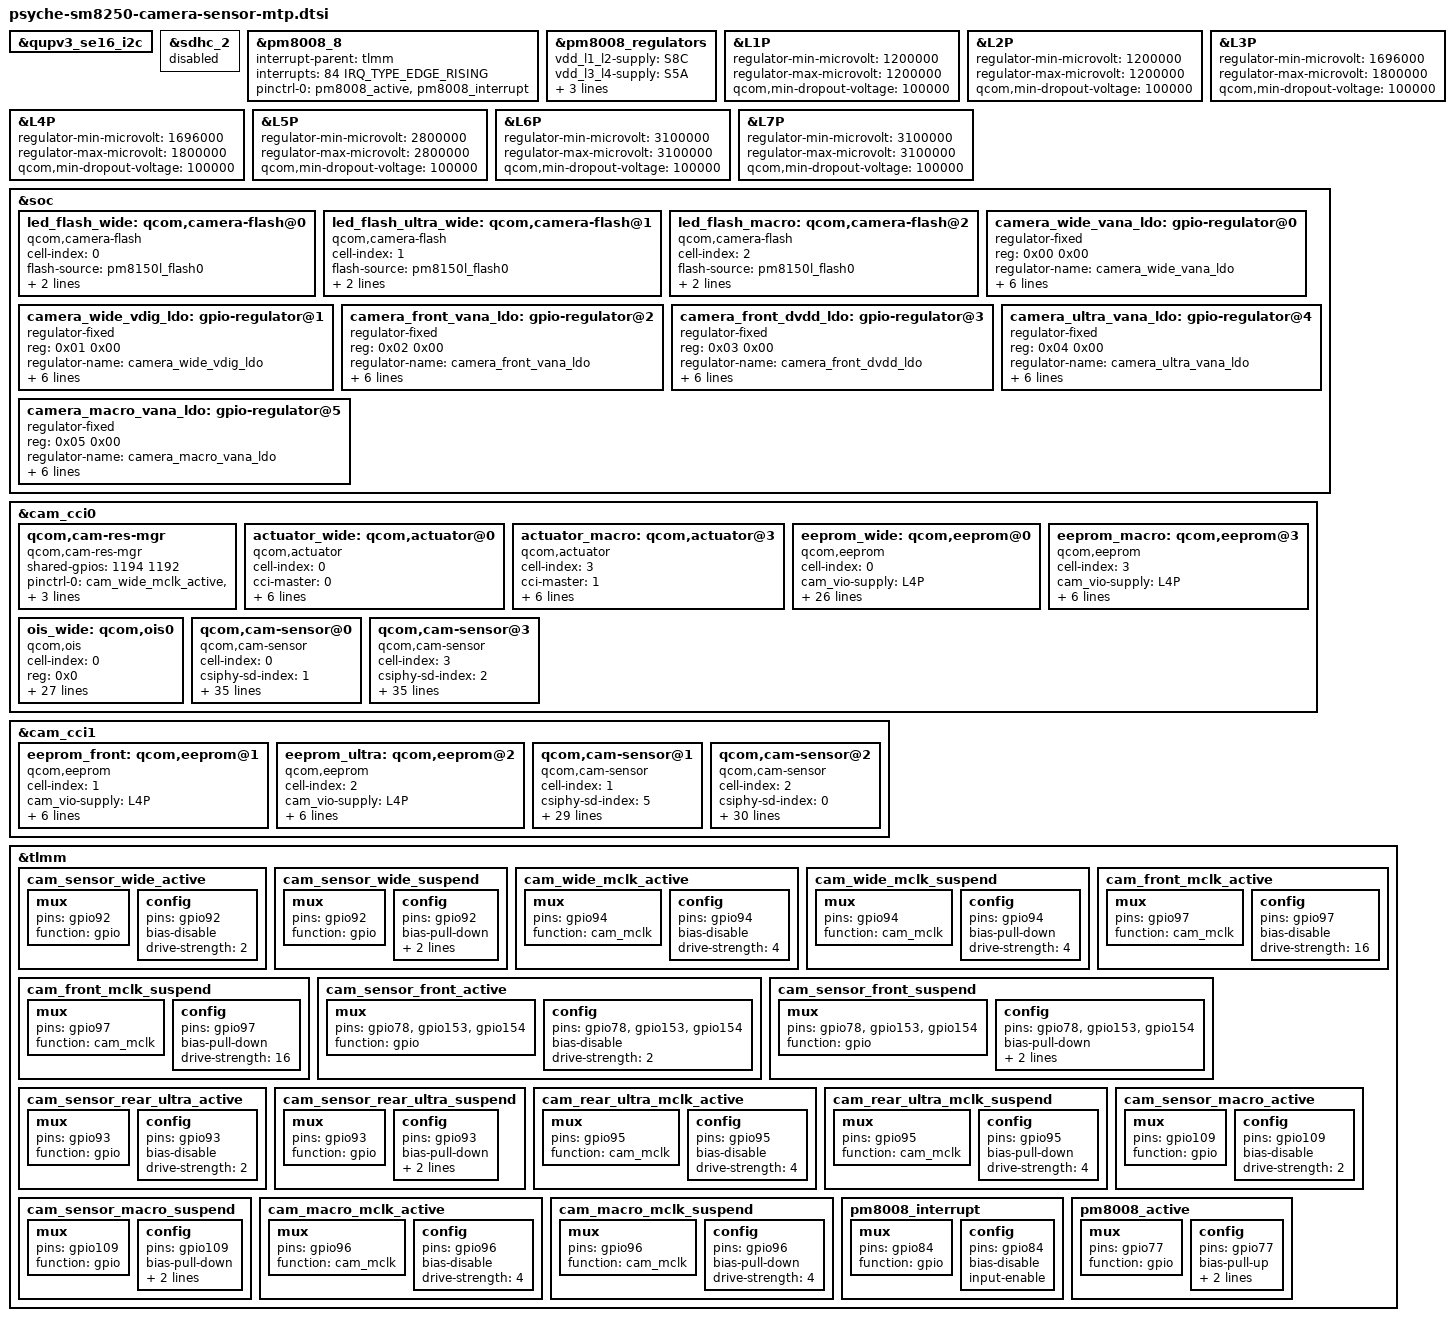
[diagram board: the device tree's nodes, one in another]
&qupv3_se16_i2c {
		status = "ok";
		#include "pm8008.dtsi"
};

&sdhc_2 {
		status = "disabled";
};

&pm8008_8 {
		/* PM8008 IRQ STAT */
		interrupt-parent = <&tlmm>;
		interrupts = <84 IRQ_TYPE_EDGE_RISING>;

		pinctrl-names = "default";
		pinctrl-0 = <&pm8008_active &pm8008_interrupt>;
};

&pm8008_regulators {
		vdd_l1_l2-supply = <&S8C>;
		vdd_l3_l4-supply = <&S5A>;
		vdd_l5-supply = <&BOB>;
		vdd_l6-supply = <&BOB>;
		vdd_l7-supply = <&BOB>;
};
&L1P {
		regulator-min-microvolt = <1200000>;
		regulator-max-microvolt = <1200000>;
		qcom,min-dropout-voltage = <100000>;
};

&L2P {
		regulator-min-microvolt = <1200000>;
		regulator-max-microvolt = <1200000>;
		qcom,min-dropout-voltage = <100000>;
};

&L3P {
		regulator-min-microvolt = <1696000>;
		regulator-max-microvolt = <1800000>;
		qcom,min-dropout-voltage = <100000>;
};

&L4P {
		regulator-min-microvolt = <1696000>;
		regulator-max-microvolt = <1800000>;
		qcom,min-dropout-voltage = <100000>;
};

&L5P {
		regulator-min-microvolt = <2800000>;
		regulator-max-microvolt = <2800000>;
		qcom,min-dropout-voltage = <100000>;
};

&L6P {
		regulator-min-microvolt = <3100000>;
		regulator-max-microvolt = <3100000>;
		qcom,min-dropout-voltage = <100000>;
};

&L7P {
		regulator-min-microvolt = <3100000>;
		regulator-max-microvolt = <3100000>;
		qcom,min-dropout-voltage = <100000>;
};

&soc {
	led_flash_wide: qcom,camera-flash@0 {
		cell-index = <0>;
		compatible = "qcom,camera-flash";
		flash-source = <&pm8150l_flash0>;
		torch-source = <&pm8150l_torch0>;
		switch-source = <&pm8150l_switch0>;
		status = "ok";
	};

	led_flash_ultra_wide: qcom,camera-flash@1 {
		cell-index = <1>;
		compatible = "qcom,camera-flash";
		flash-source = <&pm8150l_flash0>;
		torch-source = <&pm8150l_torch0>;
		switch-source = <&pm8150l_switch0>;
		status = "ok";
	};

	led_flash_macro: qcom,camera-flash@2 {
		cell-index = <2>;
		compatible = "qcom,camera-flash";
		flash-source = <&pm8150l_flash0>;
		torch-source = <&pm8150l_torch0>;
		switch-source = <&pm8150l_switch0>;
		status = "ok";
	};

	camera_wide_vana_ldo: gpio-regulator@0 {
		compatible = "regulator-fixed";
		reg = <0x00 0x00>;
		regulator-name = "camera_wide_vana_ldo";
		regulator-min-microvolt = <2800000>;
		regulator-max-microvolt = <2800000>;
		regulator-enable-ramp-delay = <135>;
		enable-active-high;
		gpio = <&tlmm 22 0>;
		vin-supply = <&pm8150a_bob>;
	};

	camera_wide_vdig_ldo: gpio-regulator@1 {
		compatible = "regulator-fixed";
		reg = <0x01 0x00>;
		regulator-name = "camera_wide_vdig_ldo";
		regulator-min-microvolt = <1150000>;
		regulator-max-microvolt = <1150000>;
		regulator-enable-ramp-delay = <135>;
		enable-active-high;
		gpio = <&tlmm 50 0>;
		vin-supply = <&S8C>;
	};

	camera_front_vana_ldo: gpio-regulator@2 {
		compatible = "regulator-fixed";
		reg = <0x02 0x00>;
		regulator-name = "camera_front_vana_ldo";
		regulator-min-microvolt = <2800000>;
		regulator-max-microvolt = <2800000>;
		regulator-enable-ramp-delay = <135>;
		enable-active-high;
		gpio = <&tlmm 153 0>;
		vin-supply = <&pm8150a_bob>;
	};

	camera_front_dvdd_ldo: gpio-regulator@3 {
		compatible = "regulator-fixed";
		reg = <0x03 0x00>;
		regulator-name = "camera_front_dvdd_ldo";
		regulator-min-microvolt = <1100000>;
		regulator-max-microvolt = <1100000>;
		regulator-enable-ramp-delay = <135>;
		enable-active-high;
		gpio = <&tlmm 154 0>;
		vin-supply = <&S8C>;
	};

	camera_ultra_vana_ldo: gpio-regulator@4 {
		compatible = "regulator-fixed";
		reg = <0x04 0x00>;
		regulator-name = "camera_ultra_vana_ldo";
		regulator-min-microvolt = <2800000>;
		regulator-max-microvolt = <2800000>;
		regulator-enable-ramp-delay = <135>;
		enable-active-high;
		gpio = <&tlmm 82 0>;
		vin-supply = <&pm8150a_bob>;
	};

	camera_macro_vana_ldo: gpio-regulator@5 {
		compatible = "regulator-fixed";
		reg = <0x05 0x00>;
		regulator-name = "camera_macro_vana_ldo";
		regulator-min-microvolt = <2800000>;
		regulator-max-microvolt = <2800000>;
		regulator-enable-ramp-delay = <135>;
		enable-active-high;
		gpio = <&tlmm 62 0>;
		vin-supply = <&pm8150a_bob>;
	};
};

&cam_cci0 {
        qcom,cam-res-mgr {
                compatible = "qcom,cam-res-mgr";
                shared-gpios = <1194 1192>;
                pinctrl-names = "cam_res_mgr_default", "cam_res_mgr_suspend";
		pinctrl-0 = <&cam_wide_mclk_active
		             &cam_sensor_wide_active>;
		pinctrl-1 = <&cam_wide_mclk_suspend
		             &cam_sensor_wide_suspend>;
                status = "ok";
        };

	/* PSYCHE Wide actuator */
	actuator_wide: qcom,actuator@0 {
		cell-index = <0>;
		compatible = "qcom,actuator";
		cci-master = <0>;
		cam_vaf-supply = <&L7P>;
		regulator-names = "cam_vaf";
		rgltr-cntrl-support;
		rgltr-min-voltage = <3100000>;
		rgltr-max-voltage = <3100000>;
		rgltr-load-current = <100000>;
		status = "ok";
	};

	/* PSYCHE macro actuator */
	actuator_macro: qcom,actuator@3 {
		cell-index = <3>;
		compatible = "qcom,actuator";
		cci-master = <1>;
		cam_vaf-supply = <&L5P>;
		regulator-names = "cam_vaf";
		rgltr-cntrl-support;
		rgltr-min-voltage = <2800000>;
		rgltr-max-voltage = <2800000>;
		rgltr-load-current = <100000>;
		status = "ok";
	};

	/* PSYCHE Wide eeprom */
	eeprom_wide: qcom,eeprom@0 {
		cell-index = <0>;
		compatible = "qcom,eeprom";
		cam_vio-supply = <&L4P>;
		cam_vana-supply = <&camera_wide_vana_ldo>; //wide avdd2 2.8v
		cam_v_custom1-supply = <&L3P>; //wide avdd1 1.8v
		cam_v_custom2-supply = <&L6P>; //wide ois 3.1v
		cam_vdig-supply = <&camera_wide_vdig_ldo>;
		cam_vaf-supply = <&L7P>;
		cam_clk-supply = <&titan_top_gdsc>;
		regulator-names = "cam_vio", "cam_vana", "cam_v_custom1", "cam_v_custom2",
                                  "cam_vdig", "cam_vaf", "cam_clk";
		rgltr-cntrl-support;
		rgltr-min-voltage = <1800000 2800000 1800000 3100000 1150000 3100000 0>;
		rgltr-max-voltage = <1800000 2800000 1800000 3100000 1150000 3100000 0>;
		rgltr-load-current = <120000 180000  80000 106000 1200000 106000 0>;
		gpio-no-mux = <0>;
		gpios = <&tlmm 94 0>,
			<&tlmm 92 0>;
		gpio-reset = <1>;
		gpio-req-tbl-num = <0 1>;
		gpio-req-tbl-flags = <1 0>;
		gpio-req-tbl-label = "CAMIF_MCLK0",
				     "CAM_RESET0";
		cci-master = <0>;
		/*use-shared-clk;*/
		clocks = <&clock_camcc CAM_CC_MCLK0_CLK>;
		clock-names = "cam_clk";
		clock-cntl-level = "turbo";
		clock-rates = <19200000>;
		status = "ok";
	};

	/* PSYCHE Macro eeprom  */
	eeprom_macro: qcom,eeprom@3 {
		cell-index = <3>;
		compatible = "qcom,eeprom";
		cam_vio-supply = <&L4P>;
		regulator-names = "cam_vio";
		rgltr-cntrl-support;
		rgltr-min-voltage = <1800000>;
		rgltr-max-voltage = <1800000>;
		rgltr-load-current = <120000>;
		cci-master = <1>;
		status = "ok";
	};

	ois_wide: qcom,ois0 {
		cell-index = <0>;
		reg = <0x0>;
		compatible = "qcom,ois";
		cam_vio-supply = <&L4P>;
		cam_vana-supply = <&camera_wide_vana_ldo>; //wide avdd2 2.8v
		cam_v_custom1-supply = <&L3P>; //wide avdd1 1.8v
		cam_v_custom2-supply = <&L6P>; //wide ois 3.1v
		cam_vdig-supply = <&camera_wide_vdig_ldo>;
		cam_vaf-supply = <&L7P>;
		cam_clk-supply = <&titan_top_gdsc>;
		regulator-names = "cam_vio", "cam_vana", "cam_v_custom1", "cam_v_custom2",
                                  "cam_vdig", "cam_vaf", "cam_clk";
		rgltr-cntrl-support;
		rgltr-min-voltage = <1800000 2800000 1800000 3100000 1150000 3100000 0>;
		rgltr-max-voltage = <1800000 2800000 1800000 3100000 1150000 3100000 0>;
		rgltr-load-current = <120000 180000  80000 106000 1200000 106000 0>;
		gpio-no-mux = <0>;
		gpios = <&tlmm 94 0>,
			<&tlmm 92 0>;
		gpio-reset = <1>;
		gpio-req-tbl-num = <0 1>;
		gpio-req-tbl-flags = <1 0>;
		gpio-req-tbl-label = "CAMIF_MCLK0",
				     "CAM_RESET0";
		cci-master = <0>;
		/*use-shared-clk;*/
		clocks = <&clock_camcc CAM_CC_MCLK0_CLK>;
		clock-names = "cam_clk";
		clock-cntl-level = "turbo";
		clock-rates = <19200000>;
		status = "ok";
	};

	/* PSYCHE Wide sensor   */
	qcom,cam-sensor@0 {
		cell-index = <0>;
		compatible = "qcom,cam-sensor";
		csiphy-sd-index = <1>;
		sensor-position-roll = <90>;
		sensor-position-pitch = <0>;
		sensor-position-yaw = <180>;
		actuator-src = <&actuator_wide>;
		led-flash-src = <&led_flash_wide>;
		eeprom-src = <&eeprom_wide>;
		ois-src = <&ois_wide>;
		cam_vio-supply = <&L4P>;
		cam_vana-supply = <&camera_wide_vana_ldo>; //wide avdd2 2.8v
		cam_v_custom1-supply = <&L3P>; //wide avdd1 1.8v
		cam_v_custom2-supply = <&L6P>; //wide ois 3.1v
		cam_vdig-supply = <&camera_wide_vdig_ldo>;
		cam_vaf-supply = <&L7P>;
		cam_clk-supply = <&titan_top_gdsc>;
		regulator-names = "cam_vio", "cam_vana", "cam_v_custom1", "cam_v_custom2",
                                  "cam_vdig", "cam_vaf", "cam_clk";
		rgltr-cntrl-support;
		rgltr-min-voltage = <1800000 2800000 1800000 3100000 1150000 3100000 0>;
		rgltr-max-voltage = <1800000 2800000 1800000 3100000 1150000 3100000 0>;
		rgltr-load-current = <120000 180000  80000 106000 1200000 106000 0>;
		gpio-no-mux = <0>;
		gpios = <&tlmm 94 0>,
			<&tlmm 92 0>;
		gpio-reset = <1>;
		gpio-req-tbl-num = <0 1>;
		gpio-req-tbl-flags = <1 0>;
		gpio-req-tbl-label = "CAMIF_MCLK0",
				     "CAM_RESET0";
		sensor-mode = <0>;
		cci-master = <0>;
		/*use-shared-clk;*/
		clocks = <&clock_camcc CAM_CC_MCLK0_CLK>;
		clock-names = "cam_clk";
		clock-cntl-level = "turbo";
		clock-rates = <19200000>;
		status = "ok";
	};

	/* PSYCHE Macro sensor  */
	qcom,cam-sensor@3 {
		cell-index = <3>;
		compatible = "qcom,cam-sensor";
		csiphy-sd-index = <2>;
		sensor-position-roll = <90>;
		sensor-position-pitch = <0>;
		sensor-position-yaw = <180>;
		actuator-src = <&actuator_macro>;
		led-flash-src = <&led_flash_macro>;
		eeprom-src = <&eeprom_macro>;
		
		cam_vio-supply = <&L4P>;
		cam_vdig-supply = <&L1P>;
		cam_vana-supply = <&camera_macro_vana_ldo>;
		cam_vaf-supply = <&L5P>;
		cam_clk-supply = <&titan_top_gdsc>;
		regulator-names = "cam_vio","cam_vdig", "cam_vana", "cam_vaf",
			"cam_clk";
		rgltr-cntrl-support;
		rgltr-min-voltage = <1800000 1200000 2800000 2800000 0>;
		rgltr-max-voltage = <1800000 1200000 2800000 2800000 0>;
		rgltr-load-current = <180000 120000 120000 106000 0>;
		gpio-no-mux = <0>;
		pinctrl-names = "cam_default", "cam_suspend";
		pinctrl-0 = <&cam_macro_mclk_active
				&cam_sensor_macro_active>;
		pinctrl-1 = <&cam_macro_mclk_suspend
				&cam_sensor_macro_suspend>;
		gpios = <&tlmm 96 0>,
			<&tlmm 109 0>;
		gpio-reset = <1>;
		gpio-req-tbl-num = <0 1>;
		gpio-req-tbl-flags = <1 0>;
		gpio-req-tbl-label = "CAMIF_MCLK2",
					"CAM_RESET2";
		sensor-mode = <0>;
		cci-master = <1>;
		clocks = <&clock_camcc CAM_CC_MCLK2_CLK>;
		clock-names = "cam_clk";
		clock-cntl-level = "turbo";
		clock-rates = <19200000>;
		status = "ok";
	};
};

&cam_cci1 {
	/* PSYCHE front eeprom */
	eeprom_front: qcom,eeprom@1 {
		cell-index = <1>;
		compatible = "qcom,eeprom";
		cam_vio-supply = <&L4P>;
		regulator-names = "cam_vio";
		rgltr-cntrl-support;
		rgltr-min-voltage = <1800000>;
		rgltr-max-voltage = <1800000>;
		rgltr-load-current = <120000>;
		cci-master = <1>;
		status = "ok";
	};

	/* ultra eeprom */
	eeprom_ultra: qcom,eeprom@2{
		cell-index = <2>;
		compatible = "qcom,eeprom";
		cam_vio-supply = <&L4P>;
		regulator-names = "cam_vio";
		rgltr-cntrl-support;
		rgltr-min-voltage = <1800000>;
		rgltr-max-voltage = <1800000>;
		rgltr-load-current = <10000>;
		cci-master = <1>;
		status = "ok";
	};

	/* PSYCHE Front  */
	qcom,cam-sensor@1 {
		cell-index = <1>;
		compatible = "qcom,cam-sensor";
		csiphy-sd-index = <5>;
		sensor-position-roll = <270>;
		sensor-position-pitch = <0>;
		sensor-position-yaw = <0>;
		eeprom-src = <&eeprom_front>;
		cam_vio-supply = <&L4P>;
		cam_vana-supply = <&camera_front_vana_ldo>;
		cam_vdig-supply = <&camera_front_dvdd_ldo>;
		cam_clk-supply = <&titan_top_gdsc>;
		regulator-names = "cam_vio", "cam_vana", "cam_vdig", "cam_clk";
		rgltr-cntrl-support;
		rgltr-min-voltage = <1800000 2800000 1100000 0>;
		rgltr-max-voltage = <1800000 2800000 1100000 0>;
		rgltr-load-current = <120000 120000 120000 0>;
		gpio-no-mux = <0>;
		pinctrl-names = "cam_default", "cam_suspend";
		pinctrl-0 = <&cam_sensor_mclk3_active
					&cam_sensor_front_active>;
		pinctrl-1 = <&cam_sensor_mclk3_suspend
					&cam_sensor_front_suspend>;
		gpios = <&tlmm 97 0>,
				<&tlmm 78 0>;
		gpio-reset = <1>;
		gpio-req-tbl-num = <0 1>;
		gpio-req-tbl-flags = <1 0>;
		gpio-req-tbl-label = "CAMIF_MCLK3",
					"CAM_RESET3";
		sensor-mode = <0>;
		cci-master = <1>;
		status = "ok";
		clocks = <&clock_camcc CAM_CC_MCLK3_CLK>;
		clock-names = "cam_clk";
		clock-cntl-level = "turbo";
		clock-rates = <19200000>;
	};

	/* PSYCHE  sensor */
	qcom,cam-sensor@2{
		cell-index = <2>;
		compatible = "qcom,cam-sensor";
		csiphy-sd-index = <0>;
		sensor-position-roll = <90>;
		sensor-position-pitch = <0>;
		sensor-position-yaw = <180>;
		eeprom-src = <&eeprom_ultra>;
		led-flash-src = <&led_flash_ultra_wide>;
		cam_vio-supply = <&L4P>;
		cam_vdig-supply = <&L2P>;
		cam_vana-supply = <&camera_ultra_vana_ldo>;
		cam_clk-supply = <&titan_top_gdsc>;
		regulator-names = "cam_vio", "cam_vdig", "cam_vana", "cam_clk";
		rgltr-cntrl-support;
		rgltr-min-voltage = <1800000 1200000 2800000 0>;
		rgltr-max-voltage = <1800000 1200000 2800000 0>;
		rgltr-load-current = <10000 140000 180000 0>;
		gpio-no-mux = <0>;
		pinctrl-names = "cam_default", "cam_suspend";
		pinctrl-0 = <&cam_rear_ultra_mclk_active
				 &cam_sensor_rear_ultra_active>;
		pinctrl-1 = <&cam_rear_ultra_mclk_suspend
				 &cam_sensor_rear_ultra_suspend>;
		gpios = <&tlmm 95 0>,
				<&tlmm 93 0>;
		gpio-reset = <1>;
		gpio-req-tbl-num = <0 1>;
		gpio-req-tbl-flags = <1 0>;
		gpio-req-tbl-label = "CAMIF_MCLK1",
					"CAM_RESET1";
		sensor-mode = <0>;
		cci-master = <1>;
		clocks = <&clock_camcc CAM_CC_MCLK1_CLK>;
		clock-names = "cam_clk";
		clock-cntl-level = "turbo";
		clock-rates = <19200000>;
		status = "ok";
	};
};

&tlmm {
	cam_sensor_wide_active: cam_sensor_wide_active {
		/* RESET WIDE */
		mux {
			pins = "gpio92";
			function = "gpio";
		};

		config {
			pins = "gpio92";
			bias-disable; /* No PULL */
			drive-strength = <2>; /* 2 MA */
		};
	};
	cam_sensor_wide_suspend: cam_sensor_wide_suspend {
		mux {
			pins = "gpio92";
			function = "gpio";
		};

		config {
			pins = "gpio92";
			bias-pull-down; /* PULL DOWN */
			drive-strength = <2>; /* 2 MA */
			output-low;
		};
	};
	cam_wide_mclk_active: cam_wide_mclk_active {
		mux {
			pins = "gpio94";
			function = "cam_mclk";
		};

		config {
			pins = "gpio94";
			bias-disable; /* No PULL */
			drive-strength = <4>; /* 4 MA */
		};
	};
	cam_wide_mclk_suspend: cam_wide_mclk_suspend {
		mux {
			pins = "gpio94";
			function = "cam_mclk";
		};

		config {
			pins = "gpio94";
			bias-pull-down; /* PULL DOWN */
			drive-strength = <4>; /* 4 MA */
		};
	};
	cam_front_mclk_active: cam_front_mclk_active {
		mux {
			pins = "gpio97";
			function = "cam_mclk";
		};

		config {
			pins = "gpio97";
			bias-disable; /* No PULL */
			drive-strength = <16>; /* 4 MA */
		};
	};
	cam_front_mclk_suspend: cam_front_mclk_suspend {
		mux {
			pins = "gpio97";
			function = "cam_mclk";
		};

		config {
			pins = "gpio97";
			bias-pull-down; /* PULL DOWN */
			drive-strength = <16>; /* 4 MA */
		};
	};
	cam_sensor_front_active: cam_sensor_front_active {
		/* RESET FRONT */
		mux {
			pins = "gpio78","gpio153","gpio154";
			function = "gpio";
		};

		config {
			pins = "gpio78","gpio153","gpio154";
			bias-disable; /* No PULL */
			drive-strength = <2>; /* 2 MA */
		};
	};
	cam_sensor_front_suspend: cam_sensor_front_suspend {
		mux {
			pins = "gpio78","gpio153","gpio154";
			function = "gpio";
		};

		config {
			pins = "gpio78","gpio153","gpio154";
			bias-pull-down; /* PULL DOWN */
			drive-strength = <2>; /* 2 MA */
			output-low;
		};
	};
	cam_sensor_rear_ultra_active: cam_sensor_rear_ultra_active {
		mux {
				pins = "gpio93";
				function = "gpio";
		};
		config {
				pins = "gpio93";
				bias-disable; /* No PULL */
				drive-strength = <2>; /* 2 MA */
		};
	};
	cam_sensor_rear_ultra_suspend: cam_sensor_rear_ultra_suspend {
		mux {
				pins = "gpio93";
				function = "gpio";
		};
		config {
				pins = "gpio93";
				bias-pull-down; /* PULL DOWN */
				drive-strength = <2>; /* 2 MA */
				output-low;
		};
	};
	cam_rear_ultra_mclk_active: cam_rear_ultra_mclk_active {
		mux {
			pins = "gpio95";
			function = "cam_mclk";
		};
		config {
			pins = "gpio95";
			bias-disable; /* No PULL */
			drive-strength = <4>; /* 4 MA */
		};
	};
	cam_rear_ultra_mclk_suspend: cam_rear_ultra_mclk_suspend {
		mux {
			pins = "gpio95";
			function = "cam_mclk";
		};
		config {
			pins = "gpio95";
			bias-pull-down; /* PULL DOWN */
			drive-strength = <4>; /* 4 MA */
		};
	};
	cam_sensor_macro_active: cam_sensor_macro_active {
		/* RESET MACRO */
		mux {
			pins = "gpio109";
			function = "gpio";
		};

		config {
			pins = "gpio109";
			bias-disable; /* No PULL */
			drive-strength = <2>; /* 2 MA */
		};
	};
	cam_sensor_macro_suspend: cam_sensor_macro_suspend {
		mux {
			pins = "gpio109";
			function = "gpio";
		};

		config {
			pins = "gpio109";
			bias-pull-down; /* PULL DOWN */
			drive-strength = <2>; /* 2 MA */
			output-low;
		};
	};
	cam_macro_mclk_active: cam_macro_mclk_active {
		mux {
			pins = "gpio96";
			function = "cam_mclk";
		};

		config {
			pins = "gpio96";
			bias-disable; /* No PULL */
			drive-strength = <4>; /* 4 MA */
		};
	};
	cam_macro_mclk_suspend: cam_macro_mclk_suspend {
		mux {
			pins = "gpio96";
			function = "cam_mclk";
		};

		config {
			pins = "gpio96";
			bias-pull-down; /* PULL DOWN */
			drive-strength = <4>; /* 4 MA */
		};
	};
};

&tlmm{
	pm8008_interrupt: pm8008_interrupt {
		mux {
			pins = "gpio84";
			function = "gpio";
		};

		config {
			pins = "gpio84";
			bias-disable;
			input-enable;
		};
	};

	pm8008_active: pm8008_active {
		mux {
			pins = "gpio77";
			function = "gpio";
		};

		config {
			pins = "gpio77";
			bias-pull-up;
			output-high;
			drive-strength = <2>;
		};
	};
};
